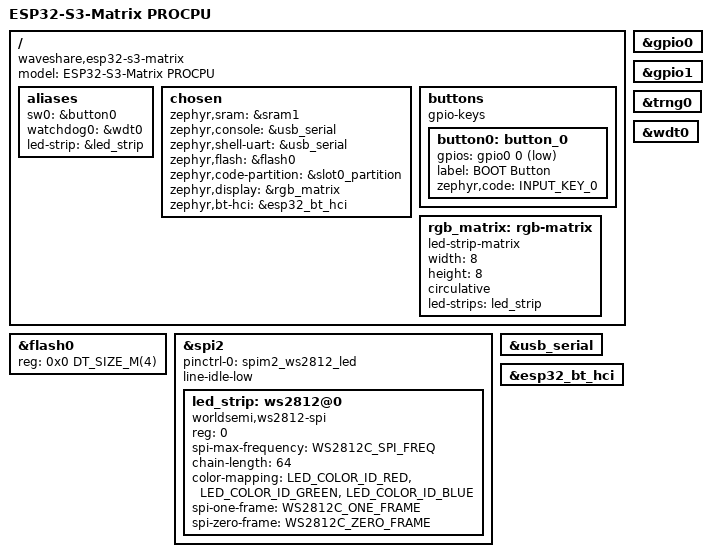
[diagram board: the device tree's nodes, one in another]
/*
 * Copyright (c) 2024 Joel Guittet
 * Copyright (c) 2025 Chen Xingyu <hi@xingrz.me>
 * SPDX-License-Identifier: Apache-2.0
 */

/dts-v1/;
#include <espressif/esp32s3/esp32s3_r2.dtsi>
#include <espressif/partitions_0x0_amp_4M.dtsi>
#include <zephyr/dt-bindings/input/input-event-codes.h>
#include <zephyr/dt-bindings/led/led.h>
#include <zephyr/dt-bindings/led/worldsemi_ws2812c.h>
#include "esp32s3_matrix-pinctrl.dtsi"

/ {
	model = "ESP32-S3-Matrix PROCPU";
	compatible = "waveshare,esp32-s3-matrix";

	aliases {
		sw0 = &button0;
		watchdog0 = &wdt0;
		led-strip = &led_strip;
	};

	chosen {
		zephyr,sram = &sram1;
		zephyr,console = &usb_serial;
		zephyr,shell-uart = &usb_serial;
		zephyr,flash = &flash0;
		zephyr,code-partition = &slot0_partition;
		zephyr,display = &rgb_matrix;
		zephyr,bt-hci = &esp32_bt_hci;
	};

	buttons {
		compatible = "gpio-keys";

		button0: button_0 {
			gpios = <&gpio0 0 (GPIO_PULL_UP | GPIO_ACTIVE_LOW)>;
			label = "BOOT Button";
			zephyr,code = <INPUT_KEY_0>;
		};
	};

	rgb_matrix: rgb-matrix {
		compatible = "led-strip-matrix";
		status = "okay";
		width = <8>;
		height = <8>;
		circulative;
		led-strips = <&led_strip>;
	};
};

&flash0 {
	reg = <0x0 DT_SIZE_M(4)>;
};

&gpio0 {
	status = "okay";
};

&gpio1 {
	status = "okay";
};

&spi2 {
	status = "okay";
	#address-cells = <1>;
	#size-cells = <0>;
	pinctrl-0 = <&spim2_ws2812_led>;
	pinctrl-names = "default";
	line-idle-low;

	led_strip: ws2812@0 {
		compatible = "worldsemi,ws2812-spi";
		reg = <0>;
		spi-max-frequency = <WS2812C_SPI_FREQ>;
		chain-length = <64>;
		color-mapping = <LED_COLOR_ID_RED>,
				<LED_COLOR_ID_GREEN>,
				<LED_COLOR_ID_BLUE>;
		spi-one-frame = <WS2812C_ONE_FRAME>;
		spi-zero-frame = <WS2812C_ZERO_FRAME>;
	};
};

&usb_serial {
	status = "okay";
};

&trng0 {
	status = "okay";
};

&wdt0 {
	status = "okay";
};

&esp32_bt_hci {
	status = "okay";
};
